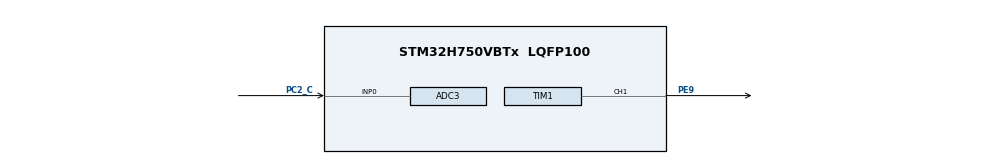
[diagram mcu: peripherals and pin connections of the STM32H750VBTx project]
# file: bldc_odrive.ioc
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ADC3.Channel-0\#ChannelRegularConversion=ADC_CHANNEL_0
ADC3.ContinuousConvMode=ENABLE
ADC3.NbrOfConversionFlag=1
ADC3.OffsetNumber-0\#ChannelRegularConversion=ADC_OFFSET_NONE
ADC3.OffsetSignedSaturation-0\#ChannelRegularConversion=DISABLE
ADC3.Rank-0\#ChannelRegularConversion=1
ADC3.SamplingTime-0\#ChannelRegularConversion=ADC_SAMPLETIME_810CYCLES_5
Bdma.ADC3.0.Direction=DMA_PERIPH_TO_MEMORY
Bdma.ADC3.0.EventEnable=DISABLE
Bdma.ADC3.0.Instance=BDMA_Channel0
Bdma.ADC3.0.MemDataAlignment=DMA_MDATAALIGN_HALFWORD
Bdma.ADC3.0.MemInc=DMA_MINC_ENABLE
Bdma.ADC3.0.Mode=DMA_CIRCULAR
Bdma.ADC3.0.PeriphDataAlignment=DMA_PDATAALIGN_HALFWORD
Bdma.ADC3.0.PeriphInc=DMA_PINC_DISABLE
Bdma.ADC3.0.Polarity=HAL_DMAMUX_REQ_GEN_RISING
Bdma.ADC3.0.Priority=DMA_PRIORITY_LOW
Bdma.ADC3.0.RequestNumber=1
Bdma.ADC3.0.SignalID=NONE
Bdma.ADC3.0.SyncEnable=DISABLE
Bdma.ADC3.0.SyncPolarity=HAL_DMAMUX_SYNC_NO_EVENT
Bdma.ADC3.0.SyncRequestNumber=1
Bdma.ADC3.0.SyncSignalID=NONE
Bdma.Request0=ADC3
Bdma.RequestsNb=1
Mcu.Family=STM32H7
Mcu.Name=STM32H750VBTx
Mcu.Package=LQFP100
NVIC.BDMA_Channel0_IRQn=true\:0\:0\:false\:false\:true\:false\:true\:true
NVIC.PriorityGroup=NVIC_PRIORITYGROUP_4
PC2_C.Mode=IN0-Single-Ended
PC2_C.Signal=ADC3_INP0
PE9.Signal=S_TIM1_CH1
PH0-OSC_IN\ (PH0).Mode=HSE-External-Oscillator
PH0-OSC_IN\ (PH0).Signal=RCC_OSC_IN
PH1-OSC_OUT\ (PH1).Mode=HSE-External-Oscillator
PH1-OSC_OUT\ (PH1).Signal=RCC_OSC_OUT
ProjectManager.HeapSize=0x200
ProjectManager.StackSize=0x400
ProjectManager.TargetToolchain=STM32CubeIDE
RCC.ADCFreq_Value=4800000
RCC.APB1Freq_Value=120000000
RCC.APB2Freq_Value=120000000
RCC.APB3Freq_Value=120000000
RCC.APB4Freq_Value=120000000
RCC.CortexFreq_Value=240000000
RCC.DIVM1=5
RCC.DIVM2=5
RCC.DIVN1=96
RCC.DIVN2=96
RCC.DIVP2=100
RCC.HCLKFreq_Value=120000000
RCC.HPRE=RCC_HCLK_DIV2
RCC.PLLSourceVirtual=RCC_PLLSOURCE_HSE
RCC.SYSCLKFreq_VALUE=240000000
RCC.SYSCLKSource=RCC_SYSCLKSOURCE_PLLCLK
RCC.USBFreq_Value=240000000
SH.S_TIM1_CH1.0=TIM1_CH1,PWM Generation1 CH1
TIM1.Channel-PWM\ Generation1\ CH1=TIM_CHANNEL_1
TIM1.Period=1000-1
TIM1.Prescaler=120-1
board=custom

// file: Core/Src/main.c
/* USER CODE BEGIN Header */
/**
  ******************************************************************************
  * @file           : main.c
  * @brief          : Main program body
  ******************************************************************************
  * @attention
  *
  * Copyright (c) 2023 STMicroelectronics.
  * All rights reserved.
  *
  * This software is licensed under terms that can be found in the LICENSE file
  * in the root directory of this software component.
  * If no LICENSE file comes with this software, it is provided AS-IS.
  *
  ******************************************************************************
  */
/* USER CODE END Header */
#include "main.h"

/* USER CODE BEGIN PTD */
#define Calibrate 1
/* USER CODE END PTD */

ADC_HandleTypeDef hadc3;
DMA_HandleTypeDef hdma_adc3;

TIM_HandleTypeDef htim1;

void SystemClock_Config(void);
static void MX_GPIO_Init(void);
static void MX_BDMA_Init(void);
static void MX_ADC3_Init(void);
static void MX_TIM1_Init(void);

/* USER CODE BEGIN 0 */
uint16_t ADC_Data=0;
int ADC_Converted = 0;

long map(long x, long in_min, long in_max, long out_min, long out_max)
{
  return (x - in_min) * (out_max - out_min + 1) / (in_max - in_min + 1) + out_min;
}

void HAL_ADC_ConvCpltCallback(ADC_HandleTypeDef* hadc)
{
	ADC_Converted = map(ADC_Data, 0, 4095, 50, 100);

	TIM1->CCR1 = ADC_Converted;
}
/* USER CODE END 0 */

int main(void)
{

  /* MCU Configuration--------------------------------------------------------*/

  /* Reset of all peripherals, Initializes the Flash interface and the Systick. */
  HAL_Init();

  /* Configure the system clock */
  SystemClock_Config();

  /* Initialize all configured peripherals */
  MX_GPIO_Init();
  MX_BDMA_Init();
  MX_ADC3_Init();
  MX_TIM1_Init();
  /* USER CODE BEGIN 2 */
  HAL_TIM_PWM_Start(&htim1, TIM_CHANNEL_1);

#if Calibrate
  TIM1->CCR1 = 100;  // Set the maximum pulse (2ms)
  HAL_Delay (2000);  // wait for 1 beep
  TIM1->CCR1 = 50;   // Set the minimum Pulse (1ms)
  HAL_Delay (1000);  // wait for 2 beeps
  TIM1->CCR1 = 0;    // reset to 0, so it can be controlled via ADC
#endif
  HAL_ADC_Start_DMA(&hadc3, (uint32_t *)&ADC_Data, 1);
  /* USER CODE END 2 */

  /* Infinite loop */
  while (1)
  {

  }
}

void SystemClock_Config(void)
{
  RCC_OscInitTypeDef RCC_OscInitStruct = {0};
  RCC_ClkInitTypeDef RCC_ClkInitStruct = {0};

  /** Supply configuration update enable
  */
  HAL_PWREx_ConfigSupply(PWR_LDO_SUPPLY);

  /** Configure the main internal regulator output voltage
  */
  __HAL_PWR_VOLTAGESCALING_CONFIG(PWR_REGULATOR_VOLTAGE_SCALE2);

  while(!__HAL_PWR_GET_FLAG(PWR_FLAG_VOSRDY)) {}

  /** Initializes the RCC Oscillators according to the specified parameters
  * in the RCC_OscInitTypeDef structure.
  */
  RCC_OscInitStruct.OscillatorType = RCC_OSCILLATORTYPE_HSE;
  RCC_OscInitStruct.HSEState = RCC_HSE_ON;
  RCC_OscInitStruct.PLL.PLLState = RCC_PLL_ON;
  RCC_OscInitStruct.PLL.PLLSource = RCC_PLLSOURCE_HSE;
  RCC_OscInitStruct.PLL.PLLM = 5;
  RCC_OscInitStruct.PLL.PLLN = 96;
  RCC_OscInitStruct.PLL.PLLP = 2;
  RCC_OscInitStruct.PLL.PLLQ = 2;
  RCC_OscInitStruct.PLL.PLLR = 2;
  RCC_OscInitStruct.PLL.PLLRGE = RCC_PLL1VCIRANGE_2;
  RCC_OscInitStruct.PLL.PLLVCOSEL = RCC_PLL1VCOWIDE;
  RCC_OscInitStruct.PLL.PLLFRACN = 0;
  if (HAL_RCC_OscConfig(&RCC_OscInitStruct) != HAL_OK)
  {
    Error_Handler();
  }

  /** Initializes the CPU, AHB and APB buses clocks
  */
  RCC_ClkInitStruct.ClockType = RCC_CLOCKTYPE_HCLK|RCC_CLOCKTYPE_SYSCLK
                              |RCC_CLOCKTYPE_PCLK1|RCC_CLOCKTYPE_PCLK2
                              |RCC_CLOCKTYPE_D3PCLK1|RCC_CLOCKTYPE_D1PCLK1;
  RCC_ClkInitStruct.SYSCLKSource = RCC_SYSCLKSOURCE_PLLCLK;
  RCC_ClkInitStruct.SYSCLKDivider = RCC_SYSCLK_DIV1;
  RCC_ClkInitStruct.AHBCLKDivider = RCC_HCLK_DIV2;
  RCC_ClkInitStruct.APB3CLKDivider = RCC_APB3_DIV1;
  RCC_ClkInitStruct.APB1CLKDivider = RCC_APB1_DIV1;
  RCC_ClkInitStruct.APB2CLKDivider = RCC_APB2_DIV1;
  RCC_ClkInitStruct.APB4CLKDivider = RCC_APB4_DIV1;

  if (HAL_RCC_ClockConfig(&RCC_ClkInitStruct, FLASH_LATENCY_2) != HAL_OK)
  {
    Error_Handler();
  }
}

static void MX_ADC3_Init(void)
{

  ADC_ChannelConfTypeDef sConfig = {0};

  /** Common config
  */
  hadc3.Instance = ADC3;
  hadc3.Init.Resolution = ADC_RESOLUTION_16B;
  hadc3.Init.ScanConvMode = ADC_SCAN_DISABLE;
  hadc3.Init.EOCSelection = ADC_EOC_SINGLE_CONV;
  hadc3.Init.LowPowerAutoWait = DISABLE;
  hadc3.Init.ContinuousConvMode = ENABLE;
  hadc3.Init.NbrOfConversion = 1;
  hadc3.Init.DiscontinuousConvMode = DISABLE;
  hadc3.Init.ExternalTrigConv = ADC_SOFTWARE_START;
  hadc3.Init.ExternalTrigConvEdge = ADC_EXTERNALTRIGCONVEDGE_NONE;
  hadc3.Init.ConversionDataManagement = ADC_CONVERSIONDATA_DR;
  hadc3.Init.Overrun = ADC_OVR_DATA_PRESERVED;
  hadc3.Init.LeftBitShift = ADC_LEFTBITSHIFT_NONE;
  hadc3.Init.OversamplingMode = DISABLE;
  if (HAL_ADC_Init(&hadc3) != HAL_OK)
  {
    Error_Handler();
  }

  /** Configure Regular Channel
  */
  sConfig.Channel = ADC_CHANNEL_0;
  sConfig.Rank = ADC_REGULAR_RANK_1;
  sConfig.SamplingTime = ADC_SAMPLETIME_810CYCLES_5;
  sConfig.SingleDiff = ADC_SINGLE_ENDED;
  sConfig.OffsetNumber = ADC_OFFSET_NONE;
  sConfig.Offset = 0;
  sConfig.OffsetSignedSaturation = DISABLE;
  if (HAL_ADC_ConfigChannel(&hadc3, &sConfig) != HAL_OK)
  {
    Error_Handler();
  }

}

static void MX_TIM1_Init(void)
{

  TIM_MasterConfigTypeDef sMasterConfig = {0};
  TIM_OC_InitTypeDef sConfigOC = {0};
  TIM_BreakDeadTimeConfigTypeDef sBreakDeadTimeConfig = {0};

  htim1.Instance = TIM1;
  htim1.Init.Prescaler = 120-1;
  htim1.Init.CounterMode = TIM_COUNTERMODE_UP;
  htim1.Init.Period = 1000-1;
  htim1.Init.ClockDivision = TIM_CLOCKDIVISION_DIV1;
  htim1.Init.RepetitionCounter = 0;
  htim1.Init.AutoReloadPreload = TIM_AUTORELOAD_PRELOAD_DISABLE;
  if (HAL_TIM_PWM_Init(&htim1) != HAL_OK)
  {
    Error_Handler();
  }
  sMasterConfig.MasterOutputTrigger = TIM_TRGO_RESET;
  sMasterConfig.MasterOutputTrigger2 = TIM_TRGO2_RESET;
  sMasterConfig.MasterSlaveMode = TIM_MASTERSLAVEMODE_DISABLE;
  if (HAL_TIMEx_MasterConfigSynchronization(&htim1, &sMasterConfig) != HAL_OK)
  {
    Error_Handler();
  }
  sConfigOC.OCMode = TIM_OCMODE_PWM1;
  sConfigOC.Pulse = 0;
  sConfigOC.OCPolarity = TIM_OCPOLARITY_HIGH;
  sConfigOC.OCNPolarity = TIM_OCNPOLARITY_HIGH;
  sConfigOC.OCFastMode = TIM_OCFAST_DISABLE;
  sConfigOC.OCIdleState = TIM_OCIDLESTATE_RESET;
  sConfigOC.OCNIdleState = TIM_OCNIDLESTATE_RESET;
  if (HAL_TIM_PWM_ConfigChannel(&htim1, &sConfigOC, TIM_CHANNEL_1) != HAL_OK)
  {
    Error_Handler();
  }
  sBreakDeadTimeConfig.OffStateRunMode = TIM_OSSR_DISABLE;
  sBreakDeadTimeConfig.OffStateIDLEMode = TIM_OSSI_DISABLE;
  sBreakDeadTimeConfig.LockLevel = TIM_LOCKLEVEL_OFF;
  sBreakDeadTimeConfig.DeadTime = 0;
  sBreakDeadTimeConfig.BreakState = TIM_BREAK_DISABLE;
  sBreakDeadTimeConfig.BreakPolarity = TIM_BREAKPOLARITY_HIGH;
  sBreakDeadTimeConfig.BreakFilter = 0;
  sBreakDeadTimeConfig.Break2State = TIM_BREAK2_DISABLE;
  sBreakDeadTimeConfig.Break2Polarity = TIM_BREAK2POLARITY_HIGH;
  sBreakDeadTimeConfig.Break2Filter = 0;
  sBreakDeadTimeConfig.AutomaticOutput = TIM_AUTOMATICOUTPUT_DISABLE;
  if (HAL_TIMEx_ConfigBreakDeadTime(&htim1, &sBreakDeadTimeConfig) != HAL_OK)
  {
    Error_Handler();
  }
  HAL_TIM_MspPostInit(&htim1);

}

static void MX_BDMA_Init(void)
{

  /* DMA controller clock enable */
  __HAL_RCC_BDMA_CLK_ENABLE();

  /* DMA interrupt init */
  /* BDMA_Channel0_IRQn interrupt configuration */
  HAL_NVIC_SetPriority(BDMA_Channel0_IRQn, 0, 0);
  HAL_NVIC_EnableIRQ(BDMA_Channel0_IRQn);

}

static void MX_GPIO_Init(void)
{

  /* GPIO Ports Clock Enable */
  __HAL_RCC_GPIOH_CLK_ENABLE();
  __HAL_RCC_GPIOC_CLK_ENABLE();
  __HAL_RCC_GPIOE_CLK_ENABLE();

}

void Error_Handler(void)
{
  __disable_irq();
  while (1)
  {
  }
}
